# 3065PNPIRA register map
File version: 1.0
Registers are 32-bit, access per field, reset 0x0 unless marked. A register's access mark holds for its fields unless they carry their own. Offsets are from the block's base; [hi:lo] are bit positions; {n}, {i} and the like mark numbered series.

## ADC0 — ADC peripheral interface
Base 0x18000000
Same registers: ADC1 0x18001000, ADC2 0x18002000
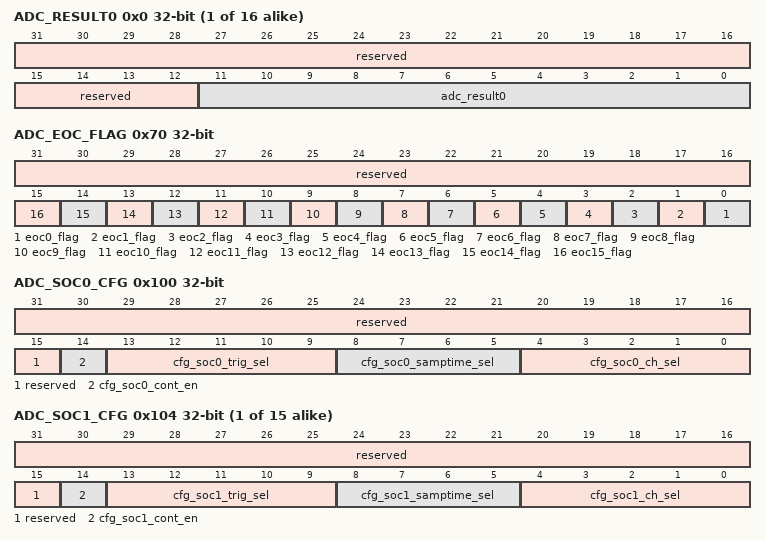
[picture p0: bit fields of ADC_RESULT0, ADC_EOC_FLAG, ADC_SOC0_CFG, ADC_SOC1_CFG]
{0x0+4i} ADC_RESULT{i} ro (i=0..15) — ADC_RESULT{i}为ADC结果寄存器{i}。
  [31:12] reserved — 保留。
  [11:0] adc_result{i} — SOC{i}结果寄存器。
0x70 ADC_EOC_FLAG — ADC_EOC_FLAG为ADC eoc状态寄存器。
  [31:16] reserved ro — 保留。
  [n] eoc{n}_flag rw write-clears (n=0..15) — SOC{n}的EOC标志寄存器。
0x100 ADC_SOC0_CFG — ADC_SOC0_CFG为ADC SOC0配置寄存器。
  [31:15] reserved ro — 保留。
  [14] cfg_soc0_cont_en rw — SOC0连续转换模式使能。 0：不使能； 1：使能。
  [13:9] cfg_soc0_trig_sel rw — SOC0触发源选择。 0：软件触发； 1：APT0_ADCA； 2：APT0_ADCB； 3：APT1_ADCA； 4：APT1_ADCB； 5：APT2_ADCA； 6：APT2_ADCB； 7：APT3_ADCA； 8：APT3_ADCB； 9：APT4_ADCA； 10：APT4_ADCB； 11：APT5_ADCA； 12：APT5_ADCB； 13：APT6_ADCA； 14：APT6_ADCB； 15：APT7_ADCA； 16：APT7_ADCB； 17：APT8_ADCA； 18：APT8_ADCB； 19：TIMER0； 20：TIMER1； 21：TIMER2； 22：TIMER3； 23：GPT0； 24：GPT1； 25：GPIO； 26：GPIO； 27：GPIO； 28：GPIO； 其他：软件触发。
  [8:5] cfg_soc0_samptime_sel rw — SOC0采样周期选择。 0x0：5clk； 0x1：7clk； 0x2：10clk； 0x3：12clk； 0x4：15clk； 0x5：22clk； 0x6：30clk； 0x7：50clk； 0x8：75clk； 0x9：100clk； 0xA：125clk； 0xB：150clk； 0xC：200clk； 0xD：300clk； 0xE：400clk； 0xF：500clk。
  [4:0] cfg_soc0_ch_sel rw — SOC0通道选择，参考23.2.5 输入信号。
{0x100+4i} ADC_SOC{i}_CFG (i=1..15) — ADC_SOC{i}_CFG为ADC SOC{i}配置寄存器。
  [31:15] reserved ro — 保留。
  [14] cfg_soc{i}_cont_en rw — SOC{i}连续转换模式使能。
  [13:9] cfg_soc{i}_trig_sel rw — SOC{i}触发源选择。
  [8:5] cfg_soc{i}_samptime_sel rw — SOC{i}采样周期选择。
  [4:0] cfg_soc{i}_ch_sel rw — SOC{i}通道选择。
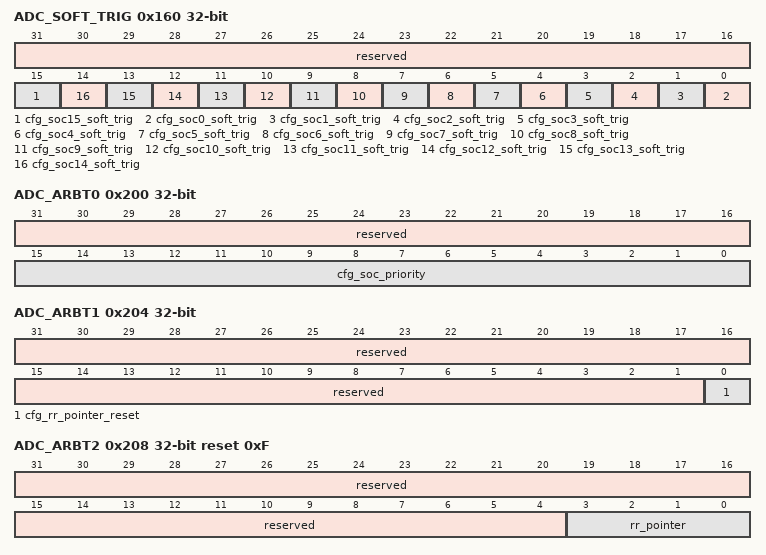
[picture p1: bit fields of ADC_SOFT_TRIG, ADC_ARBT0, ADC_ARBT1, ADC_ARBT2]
0x160 ADC_SOFT_TRIG — ADC_SOFT_TRIG为ADC软件触发寄存器。
  [31:16] reserved ro — 保留。
  [15] cfg_soc15_soft_trig rw write-1-clears — SOC15软件触发。 0：不触发； 1：触发脉冲。
  [n] cfg_soc{n}_soft_trig rw write-1-clears (n=0..14) — SOC{n}软件触发。
0x200 ADC_ARBT0 — ADC_ARBT0为ADC优先级寄存器0。
  [31:16] reserved ro — 保留。
  [15:0] cfg_soc_priority rw — SOC优先级组配置（配置对应bit位的SOC为高优先级组）。 0：轮询优先级组； 1：高优先级组。
0x204 ADC_ARBT1 — ADC_ARBT1为ADC优先级寄存器1。
  [31:1] reserved ro — 保留。
  [0] cfg_rr_pointer_reset rw write-1-clears — 轮询指针重置。 0：不重置； 1：重置指针到15。
0x208 ADC_ARBT2 ro reset 0xF — ADC_ARBT2为ADC优先级寄存器2。
  [31:4] reserved — 保留。
  [3:0] rr_pointer — 轮询指针位置。
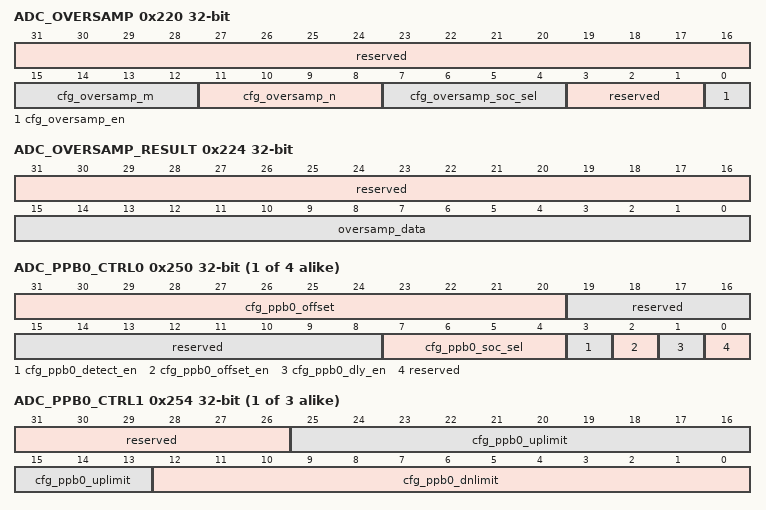
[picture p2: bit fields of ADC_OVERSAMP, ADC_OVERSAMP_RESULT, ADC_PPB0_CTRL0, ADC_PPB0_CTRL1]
0x220 ADC_OVERSAMP — ADC_OVERSAMP为ADC过采样配置寄存器。
  [31:16] reserved ro — 保留。
  [15:12] cfg_oversamp_m rw — 过采样截取精度选择，与cfg_oversamp_n联合配置，配置方式如表23-12所示。
  [11:8] cfg_oversamp_n rw — 过采样累积倍数选择。 0x3：8倍； 0x4：16倍； 0x5：32倍； 0x6：64倍； 0x7：128倍； 0x8：256倍； 其他：保留。
  [7:4] cfg_oversamp_soc_sel rw — 过采样SOC选择。 0x0：SOC0； 0x1：SOC1； … 0xF：SOC15。
  [3:1] reserved ro — 保留。
  [0] cfg_oversamp_en rw — 过采样使能。 0：不使能； 1：使能。
0x224 ADC_OVERSAMP_RESULT ro — ADC_OVERSAMP_RESULT为ADC过采样结果寄存器。
  [31:16] reserved — 保留。
  [15:0] oversamp_data — 过采样结果，低位（12bit～16bit）为有效精度。
{0x250+0x10*i} ADC_PPB{i}_CTRL0 (i=0..3) — ADC_PPB{i}_CTRL0为ADC后处理模块{i}配置寄存器0。
  [31:20] cfg_ppb{i}_offset rw — 后处理补偿offset值（有符号数，二进制补码，1bit符号位，11bit整数位）。
  [19:8] reserved ro — 保留。
  [7:4] cfg_ppb{i}_soc_sel rw — 后处理模块SOC选择。 0x0：SOC0； 0x1：SOC1； … 0xF：SOC15。
  [3] cfg_ppb{i}_detect_en rw — 后处理阈值检测使能。 0：不使能； 1：使能。
  [2] cfg_ppb{i}_offset_en rw — 后处理offset补偿使能。 0：不使能； 1：使能。
  [1] cfg_ppb{i}_dly_en rw — 后处理采样延迟计数使能。 0：不使能； 1：使能。
  [0] reserved ro — 保留。
{0x254+0x10*i} ADC_PPB{i}_CTRL1 (i=0..2) — ADC_PPB{i}_CTRL1为ADC后处理模块{i}配置寄存器1。
  [31:26] reserved ro — 保留。
  [25:13] cfg_ppb{i}_uplimit rw — 后处理误差检测上限阈值（有符号数，二进制补码，1bit符号位，12bit整数位）。
  [12:0] cfg_ppb{i}_dnlimit rw — 后处理误差检测下限阈值（有符号数，二进制补码，1bit符号位，12bit整数位）。
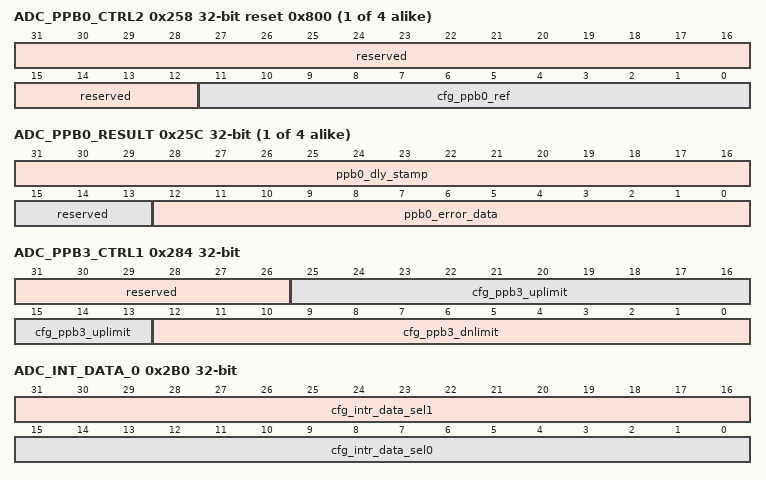
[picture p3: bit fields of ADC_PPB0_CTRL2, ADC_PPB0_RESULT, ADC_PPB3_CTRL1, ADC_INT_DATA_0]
{0x258+0x10*i} ADC_PPB{i}_CTRL2 reset 0x800 (i=0..3) — ADC_PPB{i}_CTRL2为ADC后处理模块{i}配置寄存器2。
  [31:12] reserved ro — 保留。
  [11:0] cfg_ppb{i}_ref rw — 后处理误差参考值（无符号数，12bit整数位）。
{0x25C+0x10*i} ADC_PPB{i}_RESULT ro (i=0..3) — ADC_PPB{i}_RESULT为ADC后处理模块{i}结果寄存器。
  [31:16] ppb{i}_dly_stamp — 后处理采样延迟计数值。
  [15:13] reserved — 保留。
  [12:0] ppb{i}_error_data — 后处理误差计算结果（有符号数，二进制补码，1bit符号位，12bit整数位）。
0x284 ADC_PPB3_CTRL1 — ADC_PPB3_CTRL1为ADC后处理模块3配置寄存器2。
  [31:26] reserved ro — 保留。
  [25:13] cfg_ppb3_uplimit rw — 后处理误差检测上限阈值（有符号数，二进制补码，1bit符号位，12bit整数位）。
  [12:0] cfg_ppb3_dnlimit rw — 后处理误差检测下限阈值（有符号数，二进制补码，1bit符号位，12bit整数位）。
0x2B0 ADC_INT_DATA_0 rw — ADC_INT_DATA_0为ADC数据中断配置寄存器0。
  [31:16] cfg_intr_data_sel1 — 数据中断1的SOC选择。
  [15:0] cfg_intr_data_sel0 — 数据中断0的SOC选择。
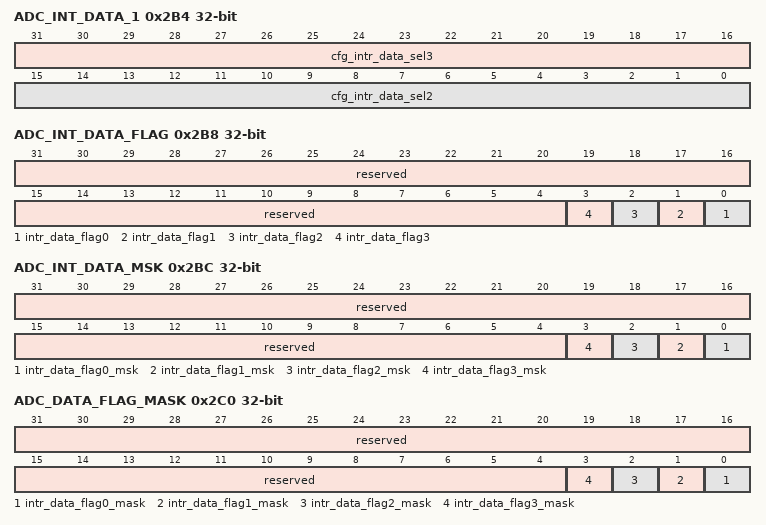
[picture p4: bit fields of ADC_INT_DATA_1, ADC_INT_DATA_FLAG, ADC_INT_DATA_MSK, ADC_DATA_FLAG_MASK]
0x2B4 ADC_INT_DATA_1 rw — ADC_INT_DATA_1为ADC数据中断配置寄存器1。
  [31:16] cfg_intr_data_sel3 — 数据中断3的SOC选择。
  [15:0] cfg_intr_data_sel2 — 数据中断2的SOC选择。
0x2B8 ADC_INT_DATA_FLAG — ADC_INT_DATA_FLAG为ADC数据中断原始状态寄存器。
  [31:4] reserved ro — 保留。
  [n] intr_data_flag{n} rw write-clears (n=0..3) — 数据中断原始状态寄存器。
0x2BC ADC_INT_DATA_MSK ro — ADC_INT_DATA_MSK为ADC数据中断屏蔽后状态寄存器。
  [31:4] reserved — 保留。
  [n] intr_data_flag{n}_msk (n=0..3) — 数据中断屏蔽后状态寄存器。
0x2C0 ADC_DATA_FLAG_MASK — ADC_DATA_FLAG_MASK为ADC数据中断屏蔽寄存器。
  [31:4] reserved ro — 保留。
  [n] intr_data_flag{n}_mask rw (n=0..3) — 数据中断屏蔽寄存器。 0：屏蔽中断； 1：不屏蔽。
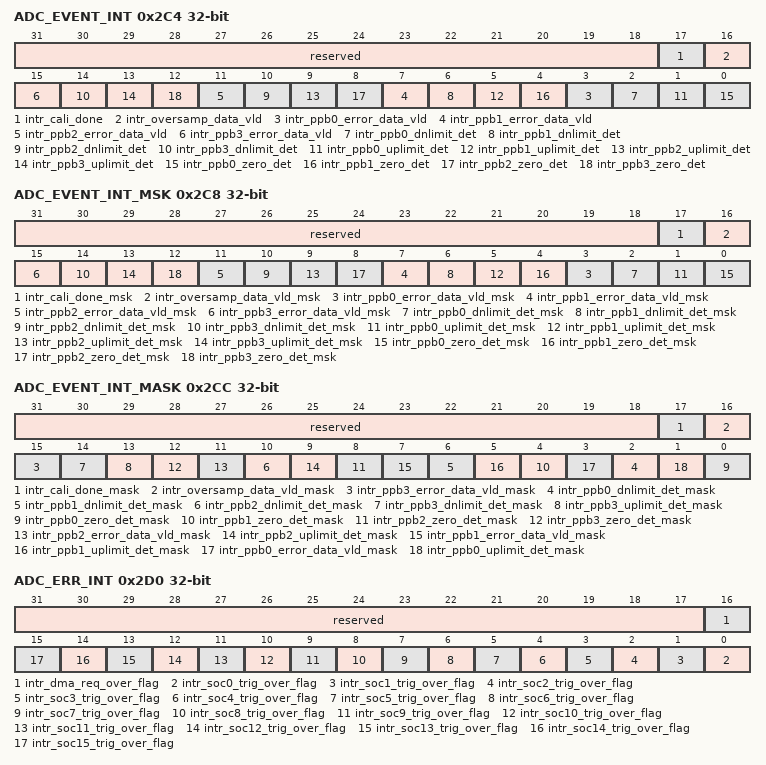
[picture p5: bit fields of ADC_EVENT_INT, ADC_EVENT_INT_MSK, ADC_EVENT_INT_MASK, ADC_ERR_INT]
0x2C4 ADC_EVENT_INT — ADC_EVENT_INT为ADC事件中断原始状态寄存器。
  [31:18] reserved ro — 保留。
  [17] intr_cali_done rw write-clears — 模式1校准完成中断原始状态寄存器。
  [16] intr_oversamp_data_vld rw write-clears — 过采样数据有效中断原始状态寄存器。
  [4n+3] intr_ppb{n}_error_data_vld rw write-clears (n=0..3) — PPB{n}误差计算数据有效中断原始状态寄存器。
  [4n+2] intr_ppb{n}_dnlimit_det rw write-clears (n=0..3) — PPB{n}下阈值超限中断原始状态寄存器。
  [4n+1] intr_ppb{n}_uplimit_det rw write-clears (n=0..3) — PPB{n}上阈值超限中断原始状态寄存器。
  [4n] intr_ppb{n}_zero_det rw write-clears (n=0..3) — PPB{n}过零点中断原始状态寄存器。
0x2C8 ADC_EVENT_INT_MSK ro — ADC_EVENT_INT_MSK为ADC事件中断屏蔽后状态寄存器。
  [31:18] reserved — 保留。
  [17] intr_cali_done_msk — 模式1校准完成中断屏蔽后状态寄存器。
  [16] intr_oversamp_data_vld_msk — 过采样数据有效中断屏蔽后状态寄存器。
  [4n+3] intr_ppb{n}_error_data_vld_msk (n=0..3) — PPB{n}误差计算数据有效中断屏蔽后状态寄存器。
  [4n+2] intr_ppb{n}_dnlimit_det_msk (n=0..3) — PPB{n}下阈值超限中断屏蔽后状态寄存器。
  [4n+1] intr_ppb{n}_uplimit_det_msk (n=0..3) — PPB{n}上阈值超限中断屏蔽后状态寄存器。
  [4n] intr_ppb{n}_zero_det_msk (n=0..3) — PPB{n}过零点中断屏蔽后状态寄存器。
0x2CC ADC_EVENT_INT_MASK — ADC_EVENT_INT_MASK为ADC事件中断屏蔽寄存器。
  [31:18] reserved ro — 保留。
  [17] intr_cali_done_mask rw — 模式1校准完成中断屏蔽寄存器。 0：屏蔽中断； 1：不屏蔽。
  [16] intr_oversamp_data_vld_mask rw — 过采样数据有效中断屏蔽寄存器。 0：屏蔽中断； 1：不屏蔽。
  [15] intr_ppb3_error_data_vld_mask rw — PPB3误差计算数据有效中断屏蔽寄存器。 0：屏蔽中断； 1：不屏蔽。
  [4n+2] intr_ppb{n}_dnlimit_det_mask rw (n=0..3) — PPB{n}下阈值超限中断屏蔽寄存器。 0：屏蔽中断； 1：不屏蔽。
  [13] intr_ppb3_uplimit_det_mask rw — PPB3上阈值超限中断屏蔽寄存器。 0：屏蔽中断； 1：不屏蔽。
  [4n] intr_ppb{n}_zero_det_mask rw (n=0..3) — PPB{n}过零点中断屏蔽寄存器。 0：屏蔽中断； 1：不屏蔽。
  [11] intr_ppb2_error_data_vld_mask rw — PPB2误差计算数据有效中断屏蔽寄存器。 0：屏蔽中断； 1：不屏蔽。
  [9] intr_ppb2_uplimit_det_mask rw — PPB2上阈值超限中断屏蔽寄存器。 0：屏蔽中断； 1：不屏蔽。
  [7] intr_ppb1_error_data_vld_mask rw — PPB1误差计算数据有效中断屏蔽寄存器。 0：屏蔽中断； 1：不屏蔽。
  [5] intr_ppb1_uplimit_det_mask rw — PPB1上阈值超限中断屏蔽寄存器。 0：屏蔽中断； 1：不屏蔽。
  [3] intr_ppb0_error_data_vld_mask rw — PPB0误差计算数据有效中断屏蔽寄存器： 0：屏蔽中断； 1：不屏蔽。
  [1] intr_ppb0_uplimit_det_mask rw — PPB0上阈值超限中断屏蔽寄存器： 0：屏蔽中断； 1：不屏蔽。
0x2D0 ADC_ERR_INT — ADC_ERR_INT为ADC异常中断原始状态寄存器。
  [31:17] reserved ro — 保留。
  [16] intr_dma_req_over_flag rw write-clears — DMA请求溢出中断原始状态寄存器。
  [n] intr_soc{n}_trig_over_flag rw write-clears (n=0..15) — SOC{n}触发溢出中断原始状态寄存器。
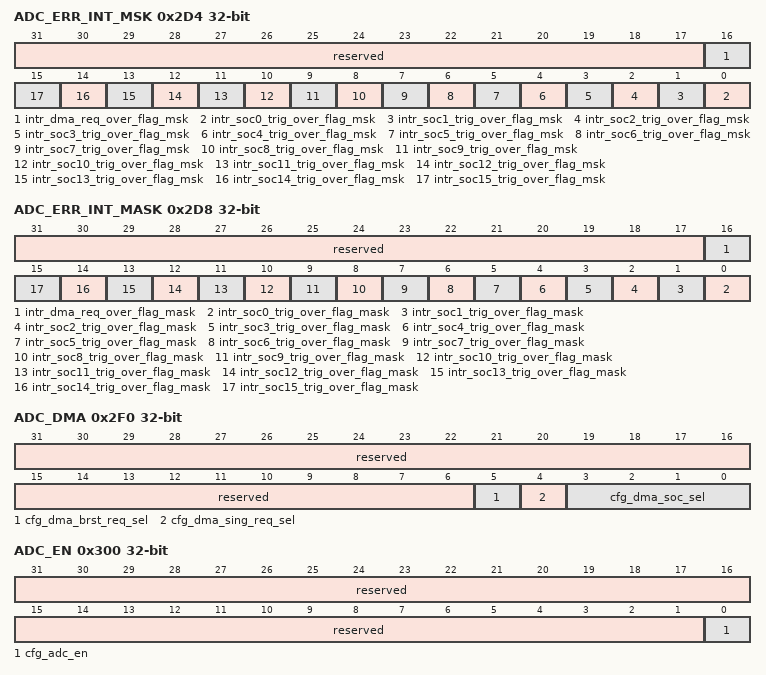
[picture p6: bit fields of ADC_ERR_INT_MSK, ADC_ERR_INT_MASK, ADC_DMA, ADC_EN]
0x2D4 ADC_ERR_INT_MSK ro — ADC_ERR_INT_MSK为ADC异常中断屏蔽后状态寄存器。
  [31:17] reserved — 保留。
  [16] intr_dma_req_over_flag_msk — DMA请求溢出中断屏蔽后状态寄存器。
  [n] intr_soc{n}_trig_over_flag_msk (n=0..15) — SOC{n}触发溢出中断屏蔽后状态寄存器。
0x2D8 ADC_ERR_INT_MASK — ADC_ERR_INT_MASK为ADC异常中断屏蔽寄存器。
  [31:17] reserved ro — 保留。
  [16] intr_dma_req_over_flag_mask rw — DMA请求溢出中断屏蔽寄存器。 0：屏蔽中断； 1：不屏蔽。
  [n] intr_soc{n}_trig_over_flag_mask rw (n=0..15) — SOC{n}触发溢出中断屏蔽寄存器。 0：屏蔽中断； 1：不屏蔽。
0x2F0 ADC_DMA — ADC_DMA为ADC DMA配置寄存器。
  [31:6] reserved ro — 保留。
  [5] cfg_dma_brst_req_sel rw — DMA BURST请求使能。 0：不使能； 1：使能。
  [4] cfg_dma_sing_req_sel rw — DMA SINGLE请求使能。 0：不使能； 1：使能。
  [3:0] cfg_dma_soc_sel rw — DMA SOC选择。 0x0：SOC0； 0x1：SOC1； … 0xF：SOC15。
0x300 ADC_EN — ADC_EN为ADC使能寄存器。
  [31:1] reserved ro — 保留。
  [0] cfg_adc_en rw — ADC使能寄存器。 0：关闭； 1：使能。
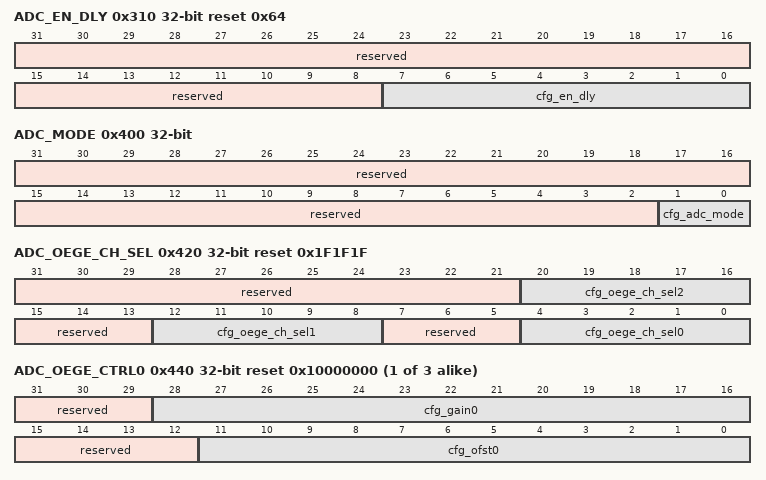
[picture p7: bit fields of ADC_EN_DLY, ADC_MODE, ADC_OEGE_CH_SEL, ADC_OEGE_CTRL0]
0x310 ADC_EN_DLY reset 0x64 — ADC_EN_DLY为ADC使能延迟寄存器。
  [31:8] reserved ro — 保留。
  [7:0] cfg_en_dly rw — ADC使能后延迟时间（us）。
0x400 ADC_MODE — ADC_MODE为ADC工作模式配置寄存器。
  [31:2] reserved ro — 保留。
  [1:0] cfg_adc_mode rw — ADC工作模式。 0：正常工作模式； 1：电容校准模式1； 其他：保留。
0x420 ADC_OEGE_CH_SEL reset 0x1F1F1F — ADC_OEGE_CH_SEL为ADC OE GE通道配置寄存器。
  [31:21] reserved ro — 保留。
  [20:16] cfg_oege_ch_sel2 rw — 连接通道选择（该配置选择的通道，由cfg_gain2/cfg_ofst2进行补偿）。
  [15:13] reserved ro — 保留。
  [12:8] cfg_oege_ch_sel1 rw — 连接通道选择（该配置选择的通道，由cfg_gain1/cfg_ofst1进行补偿）。
  [7:5] reserved ro — 保留。
  [4:0] cfg_oege_ch_sel0 rw — 连接通道选择（该配置选择的通道，由cfg_gain0/cfg_ofst0进行补偿）。
{0x440+4i} ADC_OEGE_CTRL{i} reset 0x10000000 (i=0..2) — ADC_OEGE_CTRL{i}为ADC OE GE配置寄存器{i}。
  [31:29] reserved ro — 保留。
  [28:16] cfg_gain{i} rw — 软件配置GE值（无符号数，1bit整数位，12bit小数位）。
  [15:12] reserved ro — 保留。
  [11:0] cfg_ofst{i} rw — 软件配置OE值（有符号数，二进制补码，1bit符号位，10bit整数位,1bit小数位）。
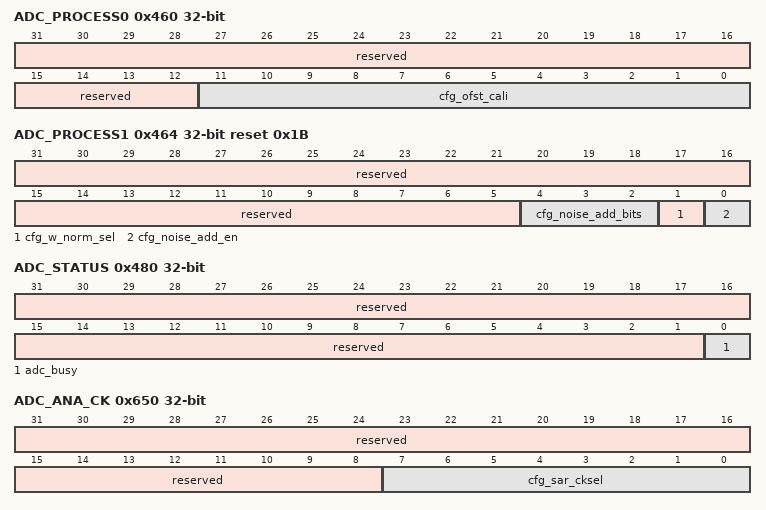
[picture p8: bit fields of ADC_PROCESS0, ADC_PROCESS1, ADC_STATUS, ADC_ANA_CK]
0x460 ADC_PROCESS0 — ADC_PROCESS0为ADC数据处理寄存器0。
  [31:12] reserved ro — 保留。
  [11:0] cfg_ofst_cali rw — 第二级OFFSET补偿值（有符号数，二进制补码，1bit符号位，10bit整数位,1bit小数位）。
0x464 ADC_PROCESS1 reset 0x1B — ADC_PROCESS1为ADC数据处理寄存器1。
  [31:5] reserved ro — 保留。
  [4:2] cfg_noise_add_bits rw — 数字加噪大小。
  [1] cfg_w_norm_sel rw — 权重归一化使能。 0：不使能； 1：使能。
  [0] cfg_noise_add_en rw — 数字加噪使能。 0：不使能； 1：使能。
0x480 ADC_STATUS ro — ADC_STATUS为ADC状态寄存器。
  [31:1] reserved — 保留。
  [0] adc_busy — ADC工作状态。 0：空闲； 1：工作中。
0x650 ADC_ANA_CK — ADC_ANA_CK为ADC模拟时钟初始化控制寄存器。
  [31:8] reserved ro — 保留。
  [7:0] cfg_sar_cksel rw — 模拟时钟初始化控制。
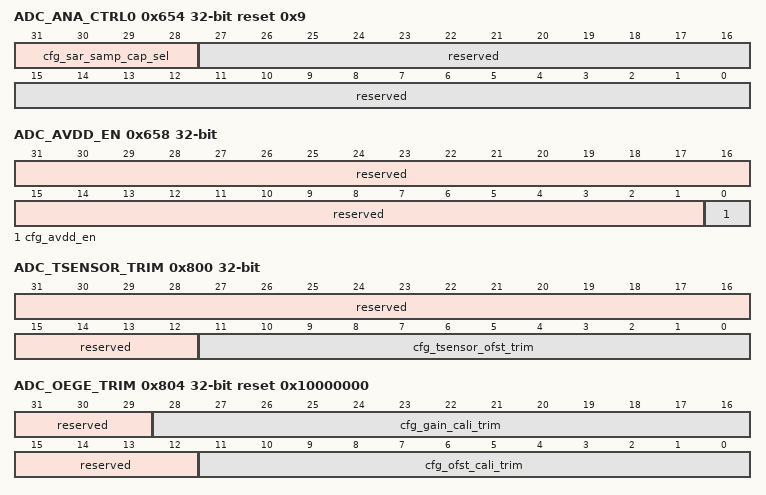
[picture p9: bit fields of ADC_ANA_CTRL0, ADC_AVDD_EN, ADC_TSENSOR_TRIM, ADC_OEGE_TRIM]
0x654 ADC_ANA_CTRL0 reset 0x9 — ADC_ANA_CTRL0为ADC模拟寄存器0。
  [31:28] cfg_sar_samp_cap_sel rw — ADC采样电容数量配置。
  [27:0] reserved ro — 保留。
0x658 ADC_AVDD_EN — ADC_AVDD_EN为AVDD通道使能寄存器。
  [31:1] reserved ro — 保留。
  [0] cfg_avdd_en rw — AVDD/3通道使能。 0：不使能； 1：使能。
0x800 ADC_TSENSOR_TRIM — ADC_TSENSOR_TRIM为Tsensor trim寄存器。
  [31:12] reserved ro — 保留。
  [11:0] cfg_tsensor_ofst_trim rw — Tsensor offset补偿trim值。
0x804 ADC_OEGE_TRIM reset 0x10000000 — ADC_OEGE_TRIM为ADC OE GE TRIM寄存器。
  [31:29] reserved ro — 保留。
  [28:16] cfg_gain_cali_trim rw — ADC通用GAIN校准trim值。
  [15:12] reserved ro — 保留。
  [11:0] cfg_ofst_cali_trim rw — ADC通用OFFSET校准trim值。
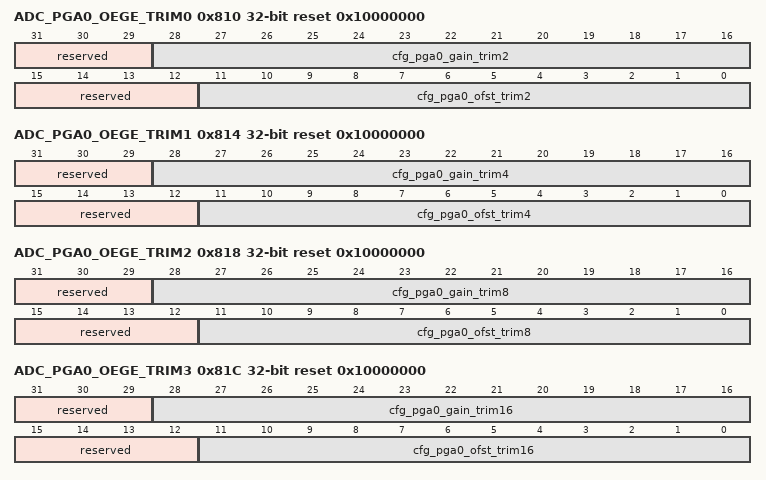
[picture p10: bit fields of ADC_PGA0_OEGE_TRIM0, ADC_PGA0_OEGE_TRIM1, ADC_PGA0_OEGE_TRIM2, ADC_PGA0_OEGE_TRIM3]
0x810 ADC_PGA0_OEGE_TRIM0 reset 0x10000000 — ADC_PGA0_OEGE_TRIM0为ADC PGA0 OE GE TRIM寄存器0。
  [31:29] reserved ro — 保留。
  [28:16] cfg_pga0_gain_trim2 rw — GAIN校准trim值。
  [15:12] reserved ro — 保留。
  [11:0] cfg_pga0_ofst_trim2 rw — OFFSET校准trim值。
0x814 ADC_PGA0_OEGE_TRIM1 reset 0x10000000 — ADC_PGA0_OEGE_TRIM1为ADC PGA0 OE GE TRIM寄存器1。
  [31:29] reserved ro — 保留。
  [28:16] cfg_pga0_gain_trim4 rw — GAIN校准trim值。
  [15:12] reserved ro — 保留。
  [11:0] cfg_pga0_ofst_trim4 rw — OFFSET校准trim值。
0x818 ADC_PGA0_OEGE_TRIM2 reset 0x10000000 — ADC_PGA0_OEGE_TRIM2为ADC PGA0 OE GE TRIM寄存器2。
  [31:29] reserved ro — 保留。
  [28:16] cfg_pga0_gain_trim8 rw — GAIN校准trim值。
  [15:12] reserved ro — 保留。
  [11:0] cfg_pga0_ofst_trim8 rw — OFFSET校准trim值。
0x81C ADC_PGA0_OEGE_TRIM3 reset 0x10000000 — ADC_PGA0_OEGE_TRIM3为ADC PGA0 OE GE TRIM寄存器3。
  [31:29] reserved ro — 保留。
  [28:16] cfg_pga0_gain_trim16 rw — GAIN校准trim值。
  [15:12] reserved ro — 保留。
  [11:0] cfg_pga0_ofst_trim16 rw — OFFSET校准trim值。
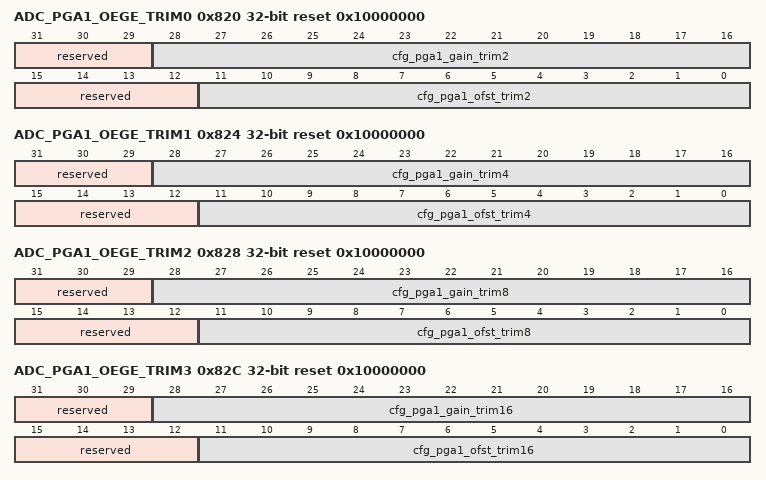
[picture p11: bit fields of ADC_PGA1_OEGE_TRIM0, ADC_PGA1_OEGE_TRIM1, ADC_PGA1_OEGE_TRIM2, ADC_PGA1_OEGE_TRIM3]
0x820 ADC_PGA1_OEGE_TRIM0 reset 0x10000000 — ADC_PGA1_OEGE_TRIM0为ADC PGA1 OE GE TRIM寄存器0。
  [31:29] reserved ro — 保留。
  [28:16] cfg_pga1_gain_trim2 rw — GAIN校准trim值。
  [15:12] reserved ro — 保留。
  [11:0] cfg_pga1_ofst_trim2 rw — OFFSET校准trim值。
0x824 ADC_PGA1_OEGE_TRIM1 reset 0x10000000 — ADC_PGA1_OEGE_TRIM1为ADC PGA1 OE GE TRIM寄存器1。
  [31:29] reserved ro — 保留。
  [28:16] cfg_pga1_gain_trim4 rw — GAIN校准trim值。
  [15:12] reserved ro — 保留。
  [11:0] cfg_pga1_ofst_trim4 rw — OFFSET校准trim值。
0x828 ADC_PGA1_OEGE_TRIM2 reset 0x10000000 — ADC_PGA1_OEGE_TRIM2为ADC PGA1 OE GE TRIM寄存器2。
  [31:29] reserved ro — 保留。
  [28:16] cfg_pga1_gain_trim8 rw — GAIN校准trim值。
  [15:12] reserved ro — 保留。
  [11:0] cfg_pga1_ofst_trim8 rw — OFFSET校准trim值。
0x82C ADC_PGA1_OEGE_TRIM3 reset 0x10000000 — ADC_PGA1_OEGE_TRIM3为ADC PGA1 OE GE TRIM寄存器3。
  [31:29] reserved ro — 保留。
  [28:16] cfg_pga1_gain_trim16 rw — GAIN校准trim值。
  [15:12] reserved ro — 保留。
  [11:0] cfg_pga1_ofst_trim16 rw — OFFSET校准trim值。
